# MKL28T7_CORE0 register map
Vendor: Freescale Semiconductor, Inc.; Series: Kinetis_L; File version: 1.6
CPU: CM0PLUS r0p0, little endian, no MPU, no FPU, VTOR, 2 interrupt priority bits
Registers are 32-bit, read-write, reset 0x0 unless marked. A register's access mark holds for its fields unless they carry their own. Offsets are from the block's base; [hi:lo] are bit positions; {n}, {i} and the like mark numbered series; 'fields as' and 'values as' point back to an identical list.

## FTFA_FlashConfig — Flash configuration field
Base 0x00000400; register names take the prefix NV_
0x00 BACKKEY3 8-bit ro reset 0xFF — Backdoor Comparison Key 3.
  [7:0] KEY — Backdoor Comparison Key.
0x01 BACKKEY2 8-bit ro reset 0xFF — Backdoor Comparison Key 2.
  [7:0] KEY — Backdoor Comparison Key.
0x02 BACKKEY1 8-bit ro reset 0xFF — Backdoor Comparison Key 1.
  [7:0] KEY — Backdoor Comparison Key.
0x03 BACKKEY0 8-bit ro reset 0xFF — Backdoor Comparison Key 0.
  [7:0] KEY — Backdoor Comparison Key.
0x04 BACKKEY7 8-bit ro reset 0xFF — Backdoor Comparison Key 7.
  [7:0] KEY — Backdoor Comparison Key.
0x05 BACKKEY6 8-bit ro reset 0xFF — Backdoor Comparison Key 6.
  [7:0] KEY — Backdoor Comparison Key.
0x06 BACKKEY5 8-bit ro reset 0xFF — Backdoor Comparison Key 5.
  [7:0] KEY — Backdoor Comparison Key.
0x07 BACKKEY4 8-bit ro reset 0xFF — Backdoor Comparison Key 4.
  [7:0] KEY — Backdoor Comparison Key.
0x08 FPROT3 8-bit ro reset 0xFF — Non-volatile P-Flash Protection 1 - Low Register
  [7:0] PROT — P-Flash Region Protect
0x09 FPROT2 8-bit ro reset 0xFF — Non-volatile P-Flash Protection 1 - High Register
  [7:0] PROT — P-Flash Region Protect
0x0A FPROT1 8-bit ro reset 0xFF — Non-volatile P-Flash Protection 0 - Low Register
  [7:0] PROT — P-Flash Region Protect
0x0B FPROT0 8-bit ro reset 0xFF — Non-volatile P-Flash Protection 0 - High Register
  [7:0] PROT — P-Flash Region Protect
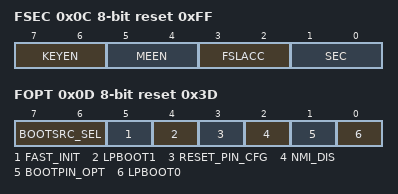
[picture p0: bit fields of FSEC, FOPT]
0x0C FSEC 8-bit ro reset 0xFF — Non-volatile Flash Security Register
  [7:6] KEYEN — Backdoor Key Security Enable
    2=Backdoor key access enabled; 3=Backdoor key access disabled
  [5:4] MEEN
    2=Mass erase is disabled; 3=Mass erase is enabled
  [3:2] FSLACC — Freescale Failure Analysis Access Code
    2=Freescale factory access denied; 3=Freescale factory access granted
  [1:0] SEC — Flash Security
    2=MCU security status is unsecure; 3=MCU security status is secure
0x0D FOPT 8-bit ro reset 0x3D — Non-volatile Flash Option Register
  [7:6] BOOTSRC_SEL — Boot source selection
    0=Boot from Flash; 2=Boot from ROM; 3=Boot from ROM
  [5] FAST_INIT
    0=Slower initialization; 1=Fast Initialization
  [4] LPBOOT1
    0=Core and system clock divider (OUTDIV1) is 0x7 (divide by 8) when LPBOOT0=0 or 0x3 (divide by 4) when LPBOOT0=1; 1=Core and system clock divider (OUTDIV1) is 0x1 (divide by 2) when LPBOOT0=0 or 0x0 (divide by 1) when LPBOOT0=1
  [3] RESET_PIN_CFG
    0=RESET pin is disabled following a POR and cannot be enabled as reset function; 1=RESET_b pin is dedicated
  [2] NMI_DIS
    0=NMI interrupts are always blocked; 1=NMI_b pin/interrupts reset default to enabled
  [1] BOOTPIN_OPT
    0=Force Boot from ROM if BOOTCFG0 asserted, where BOOTCFG0 is the boot config function which is muxed with NMI pin; 1=Boot source configured by FOPT (BOOTSRC_SEL) bits
  [0] LPBOOT0
    0=Core and system clock divider (OUTDIV1) is 0x7 (divide by 8) when LPBOOT1=0 or 0x1 (divide by 2) when LPBOOT1=1; 1=Core and system clock divider (OUTDIV1) is 0x3 (divide by 4) when LPBOOT1=0 or 0x0 (divide by 1) when LPBOOT1=1

## MSCM
Base 0x40001000; register names take the prefix MSCM_
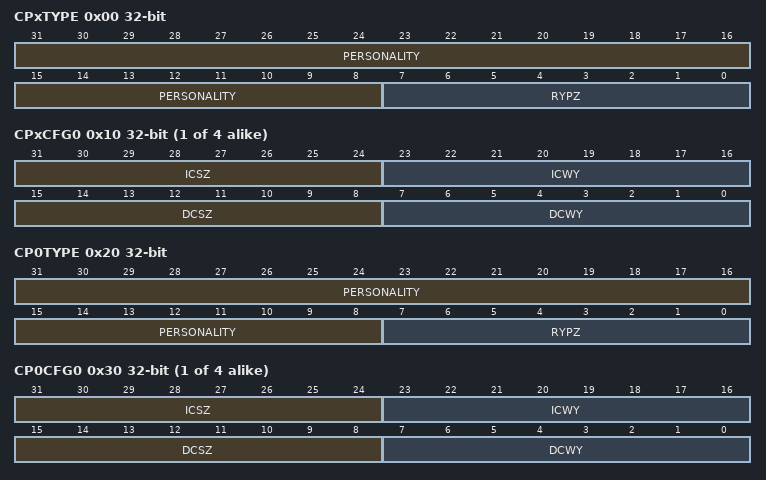
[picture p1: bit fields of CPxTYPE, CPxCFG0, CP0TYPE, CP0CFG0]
0x00 CPxTYPE ro — Processor X Type Register
  [31:8] PERSONALITY — Processor x Personality
  [7:0] RYPZ — Processor x Revision
0x04 CPxNUM ro — Processor X Number Register
  [0] CPN — Processor x Number
0x08 CPxMASTER ro — Processor X Master Register
  [5:0] PPN — Processor x Physical Port Number
0x0C CPxCOUNT ro — Processor X Count Register
  [1:0] PCNT — Processor Count
{0x10+4i} CPxCFG{i} (i=0..3) ro — Processor X Configuration Register
  [31:24] ICSZ — Level 1 Instruction Cache Size
  [23:16] ICWY — Level 1 Instruction Cache Ways
  [15:8] DCSZ — Level 1 Data Cache Size
  [7:0] DCWY — Level 1 Data Cache Ways
0x20 CP0TYPE ro — Processor 0 Type Register
  fields as CPxTYPE
0x24 CP0NUM ro — Processor 0 Number Register
  [0] CPN — Processor x Number
0x28 CP0MASTER ro — Processor 0 Master Register
  [5:0] PPN — Processor x Physical Port Number
0x2C CP0COUNT ro — Processor 0 Count Register
  [1:0] PCNT — Processor Count
{0x30+4i} CP0CFG{i} (i=0..3) ro — Processor 0 Configuration Register
  fields as CPxCFG0
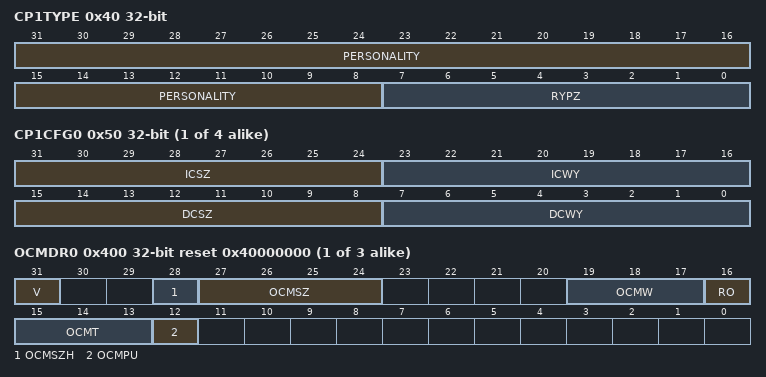
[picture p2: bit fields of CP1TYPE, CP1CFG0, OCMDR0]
0x40 CP1TYPE ro — Processor 1 Type Register
  fields as CPxTYPE
0x44 CP1NUM ro — Processor 1 Number Register
  [0] CPN — Processor x Number
0x48 CP1MASTER ro — Processor 1 Master Register
  [5:0] PPN — Processor x Physical Port Number
0x4C CP1COUNT ro — Processor 1 Count Register
  [1:0] PCNT — Processor Count
{0x50+4i} CP1CFG{i} (i=0..3) ro — Processor 1 Configuration Register
  fields as CPxCFG0
{0x400+4i} OCMDR{i} (i=0..2) ro reset 0x40000000 (reset mask 0x40000000) — On-Chip Memory Descriptor Register
  [31] V — OCMEM Valid bit. This read-only field defines the validity (presence) of the on-chip memory
    0=OCMEMn is not present; 1=OCMEMn is present
  [28] OCMSZH — OCMEM Size "Hole"
    0=OCMEMn is a power-of-2 capacity; 1=OCMEMn is not a power-of-2, with a capacity is 0.75 * OCMSZ
  [27:24] OCMSZ — OCMEM Size
    0=no OCMEMn; 4=4KB OCMEMn; 5=8KB OCMEMn; 6=16KB OCMEMn; 7=32KB OCMEMn; 15=8192KB OCMEMn
  [19:17] OCMW — OCMEM datapath Width. This read-only field defines the width of the on-chip memory:
    2=OCMEMn 32-bits wide; 3=OCMEMn 64-bits wide
  [16] RO — Read-Only
    0=Writes to the OCMDRn[11:0] are allowed; 1=Writes to the OCMDRn[11:0] are ignored
  [15:13] OCMT — OCMEM Type. This field defines the type of the on-chip memory:
    0=OCMEMn is a system RAM; 1=OCMEMn is a graphics RAM; 3=OCMEMn is a ROM
  [12] OCMPU — OCMEM Memory Protection Unit. This read-only field identifies a memory protected by an XRDC module.
    0=OCMEMn is not protected by an XRDC module; 1=OCMEMn is protected by an XRDC module

## Notices in the file
Redistribution and use in source and binary forms, with or without modification,
are permitted provided that the following conditions are met:
o Redistributions of source code must retain the above copyright notice, this list
of conditions and the following disclaimer.
o Redistributions in binary form must reproduce the above copyright notice, this
list of conditions and the following disclaimer in the documentation and/or
other materials provided with the distribution.
o Neither the name of Freescale Semiconductor, Inc. nor the names of its
contributors may be used to endorse or promote products derived from this
software without specific prior written permission.
THIS SOFTWARE IS PROVIDED BY THE COPYRIGHT HOLDERS AND CONTRIBUTORS "AS IS" AND
ANY EXPRESS OR IMPLIED WARRANTIES, INCLUDING, BUT NOT LIMITED TO, THE IMPLIED
WARRANTIES OF MERCHANTABILITY AND FITNESS FOR A PARTICULAR PURPOSE ARE
DISCLAIMED. IN NO EVENT SHALL THE COPYRIGHT HOLDER OR CONTRIBUTORS BE LIABLE FOR
ANY DIRECT, INDIRECT, INCIDENTAL, SPECIAL, EXEMPLARY, OR CONSEQUENTIAL DAMAGES
(INCLUDING, BUT NOT LIMITED TO, PROCUREMENT OF SUBSTITUTE GOODS OR SERVICES;
LOSS OF USE, DATA, OR PROFITS; OR BUSINESS INTERRUPTION) HOWEVER CAUSED AND ON
ANY THEORY OF LIABILITY, WHETHER IN CONTRACT, STRICT LIABILITY, OR TORT
(INCLUDING NEGLIGENCE OR OTHERWISE) ARISING IN ANY WAY OUT OF THE USE OF THIS
SOFTWARE, EVEN IF ADVISED OF THE POSSIBILITY OF SUCH DAMAGE.
